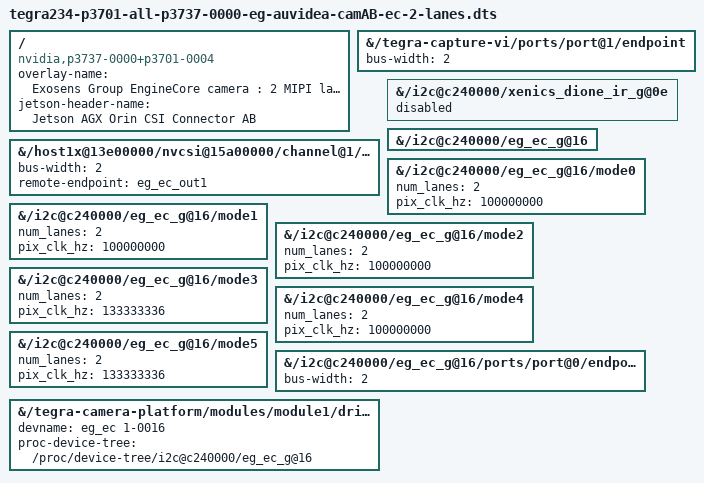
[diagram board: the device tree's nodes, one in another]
// SPDX-License-Identifier: GPL-2.0-only
/*
 * Jetson Device-tree overlay for Camera E3331 on t23x platforms
 *
 * Copyright (c) 2022 NVIDIA CORPORATION. All rights reserved.
 *
 */


/dts-v1/;
/plugin/;


/ {
	overlay-name = "Exosens Group EngineCore camera : 2 MIPI lane";
	jetson-header-name = "Jetson AGX Orin CSI Connector AB";
	compatible = "nvidia,p3737-0000+p3701-0004", "nvidia,tegra234", "nvidia,tegra23x";

	fragment@0 {
		target-path = "/tegra-capture-vi/ports/port@1/endpoint";
		__overlay__ {
			bus-width=<2>;
		};
	};

	fragment@1 {
		target-path = "/host1x@13e00000/nvcsi@15a00000/channel@1/ports/port@0/endpoint@0";
		__overlay__ {
			bus-width=<2>;
         remote-endpoint = <&eg_ec_out1>;
		};
	};

   // Disable Dione cameras
	fragment@2 {
		target-path = "/i2c@c240000/xenics_dione_ir_g@0e";
		__overlay__ {
         status = "disabled";
		};
	};

   // Enable EngineCore cameras
	fragment@3 {
		target-path = "/i2c@c240000/eg_ec_g@16";
		__overlay__ {
         status = "okay";
		};
	};
	fragment@4 {   
		target-path = "/i2c@c240000/eg_ec_g@16/mode0";
		__overlay__ {
         num_lanes = "2";
         pix_clk_hz = "100000000";
		};
	};
	fragment@5 {
		target-path = "/i2c@c240000/eg_ec_g@16/mode1";
		__overlay__ {
         num_lanes = "2";
         pix_clk_hz = "100000000";
		};
	};
	fragment@6 {
		target-path = "/i2c@c240000/eg_ec_g@16/mode2";
		__overlay__ {
         num_lanes = "2";
         pix_clk_hz = "100000000";
		};
	};
	fragment@7 {
		target-path = "/i2c@c240000/eg_ec_g@16/mode3";
		__overlay__ {
         num_lanes = "2";
         pix_clk_hz = "133333336";
		};
	};
	fragment@8 {
		target-path = "/i2c@c240000/eg_ec_g@16/mode4";
		__overlay__ {
         num_lanes = "2";
         pix_clk_hz = "100000000";
		};
	};
	fragment@9 {
		target-path = "/i2c@c240000/eg_ec_g@16/mode5";
		__overlay__ {
         num_lanes = "2";
         pix_clk_hz = "133333336";
		};
	};
	fragment@10 {
		target-path = "/i2c@c240000/eg_ec_g@16/ports/port@0/endpoint";
		__overlay__ {
			bus-width=<2>;
		};
	};

	fragment@11 {
		target-path = "/tegra-camera-platform/modules/module1/drivernode0";
		__overlay__ {
         devname = "eg_ec 1-0016";
			proc-device-tree = "/proc/device-tree/i2c@c240000/eg_ec_g@16";
		};
	};
};
